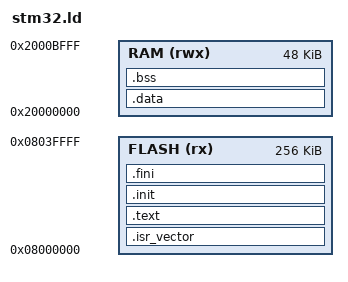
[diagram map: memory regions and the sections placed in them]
/* Linker script for STM32F103RCT6 (256K Flash, 48K RAM) */

MEMORY
{
    FLASH (rx) : ORIGIN = 0x08000000, LENGTH = 256K
    RAM (rwx)  : ORIGIN = 0x20000000, LENGTH = 48K
}

ENTRY(Reset_Handler)

_estack = ORIGIN(RAM) + LENGTH(RAM);

SECTIONS
{
    .isr_vector :
    {
        KEEP(*(.isr_vector))
    } > FLASH

    .text :
    {
        *(.text*)
        *(.rodata*)
        . = ALIGN(4);
    } > FLASH

    .init :
    {
        KEEP(*(.init))
        . = ALIGN(4);
    } > FLASH

    .fini :
    {
        KEEP(*(.fini))
        . = ALIGN(4);
        _etext = .;
    } > FLASH

    .data : AT(_etext)
    {
        _sdata = .;
        *(.data*)
        _edata = .;
    } > RAM

    .bss :
    {
        _sbss = .;
        __bss_start__ = .;
        *(.bss*)
        *(COMMON)
        _ebss = .;
        __bss_end__ = .;
    } > RAM
}
